AUTOSAR XML (schema 4-0-3)
package /ComponentTypes
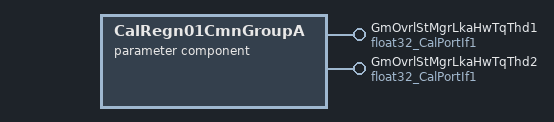
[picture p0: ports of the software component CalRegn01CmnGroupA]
  parameter sw component type CalRegn01CmnGroupA
    provide port GmOvrlStMgrLkaHwTqThd1: parameter-provide-com-spec{init-value=3, parameter=Val}, provided-interface=float32_CalPortIf1
    provide port GmOvrlStMgrLkaHwTqThd2: parameter-provide-com-spec{init-value=5, parameter=Val}, provided-interface=float32_CalPortIf1
